VERSION ""

NS_ :

BS_:

BU_: ECU TLM IMU ECU IMU TLM TLM ECU ECU ECU ECU

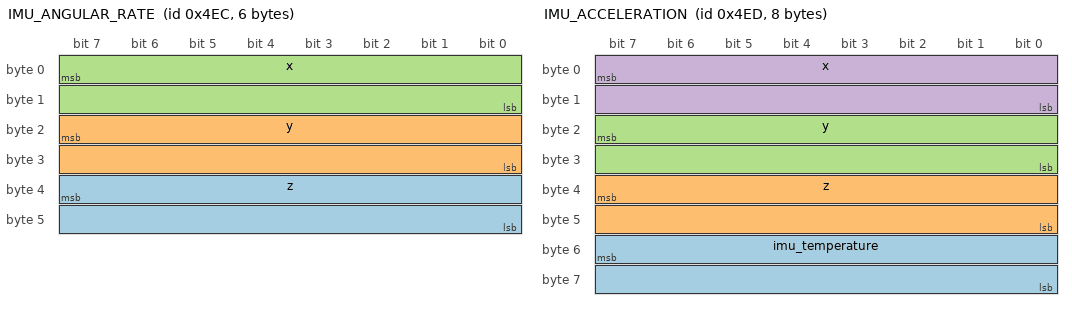
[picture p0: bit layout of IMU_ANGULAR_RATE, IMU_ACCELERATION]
BO_ 1260 IMU_ANGULAR_RATE: 6 Vector__XXX
 SG_ z : 39|16@0- (0.1,0) [0|245] "" Vector__XXX
 SG_ y : 23|16@0- (0.1,0) [0|245] "" Vector__XXX
 SG_ x : 7|16@0- (0.1,0) [0|245] "" Vector__XXX

BO_ 1261 IMU_ACCELERATION: 8 Vector__XXX
 SG_ imu_temperature : 55|16@0- (1,-32768) [-32768|32767] "" Vector__XXX
 SG_ z : 39|16@0- (0.01,0) [0|8] "" Vector__XXX
 SG_ y : 23|16@0- (0.01,0) [0|8] "" Vector__XXX
 SG_ x : 7|16@0- (0.01,0) [0|8] "" Vector__XXX

BO_ 1536 PEDAL_THROTTLE: 2 Vector__XXX
 SG_ throttle : 0|16@1+ (1.5259021896696422e-05,0) [0|1] "" Vector__XXX

BO_ 1544 PEDAL_BRAKES_PRESSURE: 4 Vector__XXX
 SG_ rear : 16|16@1+ (0.0015259021896696422,0) [0|100] "" Vector__XXX
 SG_ front : 0|16@1+ (0.0015259021896696422,0) [0|100] "" Vector__XXX

BO_ 1552 STEER_ANGLE: 4 Vector__XXX
 SG_ angle : 0|32@1+ (8.38190317349087e-08,-180) [-180|180] "" Vector__XXX

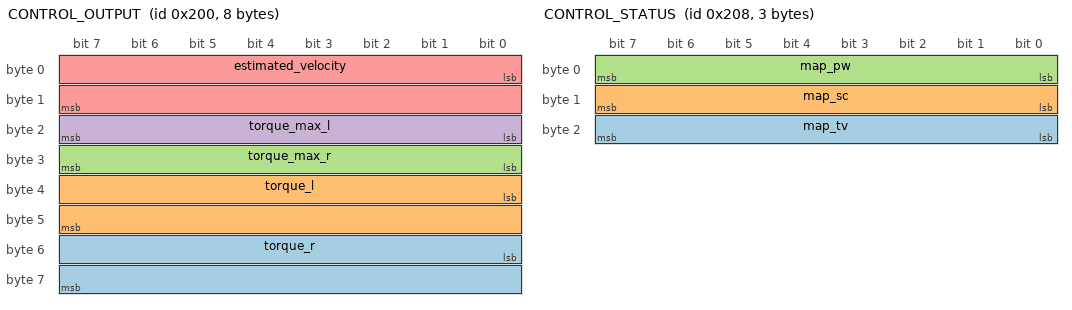
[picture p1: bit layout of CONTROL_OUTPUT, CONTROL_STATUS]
BO_ 512 CONTROL_OUTPUT: 8 Vector__XXX
 SG_ torque_r : 48|16@1+ (0.0015259021896696422,0) [0|100] "" Vector__XXX
 SG_ torque_l : 32|16@1+ (0.0015259021896696422,0) [0|100] "" Vector__XXX
 SG_ torque_max_r : 24|8@1+ (0.39215686274509803,0) [0|100] "" Vector__XXX
 SG_ torque_max_l : 16|8@1+ (0.39215686274509803,0) [0|100] "" Vector__XXX
 SG_ estimated_velocity : 0|16@1+ (0.000686655985351339,-10) [-10|35] "" Vector__XXX

BO_ 520 CONTROL_STATUS: 3 Vector__XXX
 SG_ map_tv : 16|8@1+ (0.01,0) [0|1] "" Vector__XXX
 SG_ map_sc : 8|8@1+ (0.01,0) [0|1] "" Vector__XXX
 SG_ map_pw : 0|8@1+ (0.01,-0.5) [-0.5|1] "" Vector__XXX

BO_ 1560 SPEED: 4 Vector__XXX
 SG_ fr : 16|16@1+ (0.006103608758678569,-200) [-200|200] "" Vector__XXX
 SG_ fl : 0|16@1+ (0.006103608758678569,-200) [-200|200] "" Vector__XXX

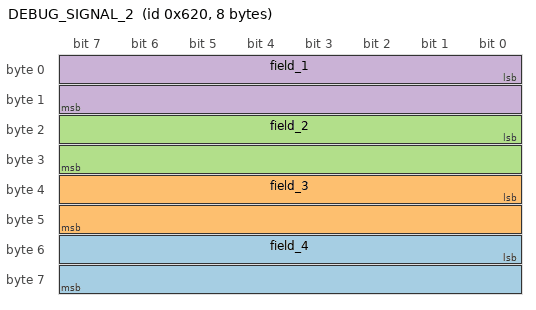
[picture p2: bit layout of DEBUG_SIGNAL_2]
BO_ 1568 DEBUG_SIGNAL_2: 8 Vector__XXX
 SG_ field_4 : 48|16@1+ (3.0518043793392844e-05,-1) [-1|1] "" Vector__XXX
 SG_ field_3 : 32|16@1+ (3.0518043793392844e-05,-1) [-1|1] "" Vector__XXX
 SG_ field_2 : 16|16@1+ (3.0518043793392844e-05,-1) [-1|1] "" Vector__XXX
 SG_ field_1 : 0|16@1+ (3.0518043793392844e-05,-1) [-1|1] "" Vector__XXX

CM_ BO_ 1260 "Inertial Measurement Unit [x,y,z]-axis angular rate value. 0.01dps per bit, Big-Endian, 16bit Total, signed";
CM_ BO_ 1261 "Inertial Measurement Unit [x,y,z]-axis acceleration value. 0.01g per bit, Big-Endian, 16bit Total, signed";
CM_ BO_ 1536 "Pedal Throttle , already calibrated";
CM_ BO_ 1544 "Pedal brakes pressures in bar, already calibrated";
CM_ BO_ 1552 "Steering angle in degrees";
CM_ BO_ 512 "Torques and signals calculated by the controls algorithms";
CM_ BO_ 520 "Power maps used by the control algotirhm. (ECU checks if are coherent with the ones in the ECU)";
CM_ BO_ 1560 "Encoder and inverter speed in rad/sec";
CM_ BO_ 1568 "Debug signals";
BA_DEF_ BO_  "GenMsgCycleTime" INT 0 65535;
BA_DEF_DEF_  "GenMsgCycleTime" 0;
BA_ "GenMsgCycleTime" BO_ 1536 10;
BA_ "GenMsgCycleTime" BO_ 1544 10;
BA_ "GenMsgCycleTime" BO_ 1552 10;
BA_ "GenMsgCycleTime" BO_ 512 20;
BA_ "GenMsgCycleTime" BO_ 520 20;
BA_ "GenMsgCycleTime" BO_ 1560 10;
BA_ "GenMsgCycleTime" BO_ 1568 10;
